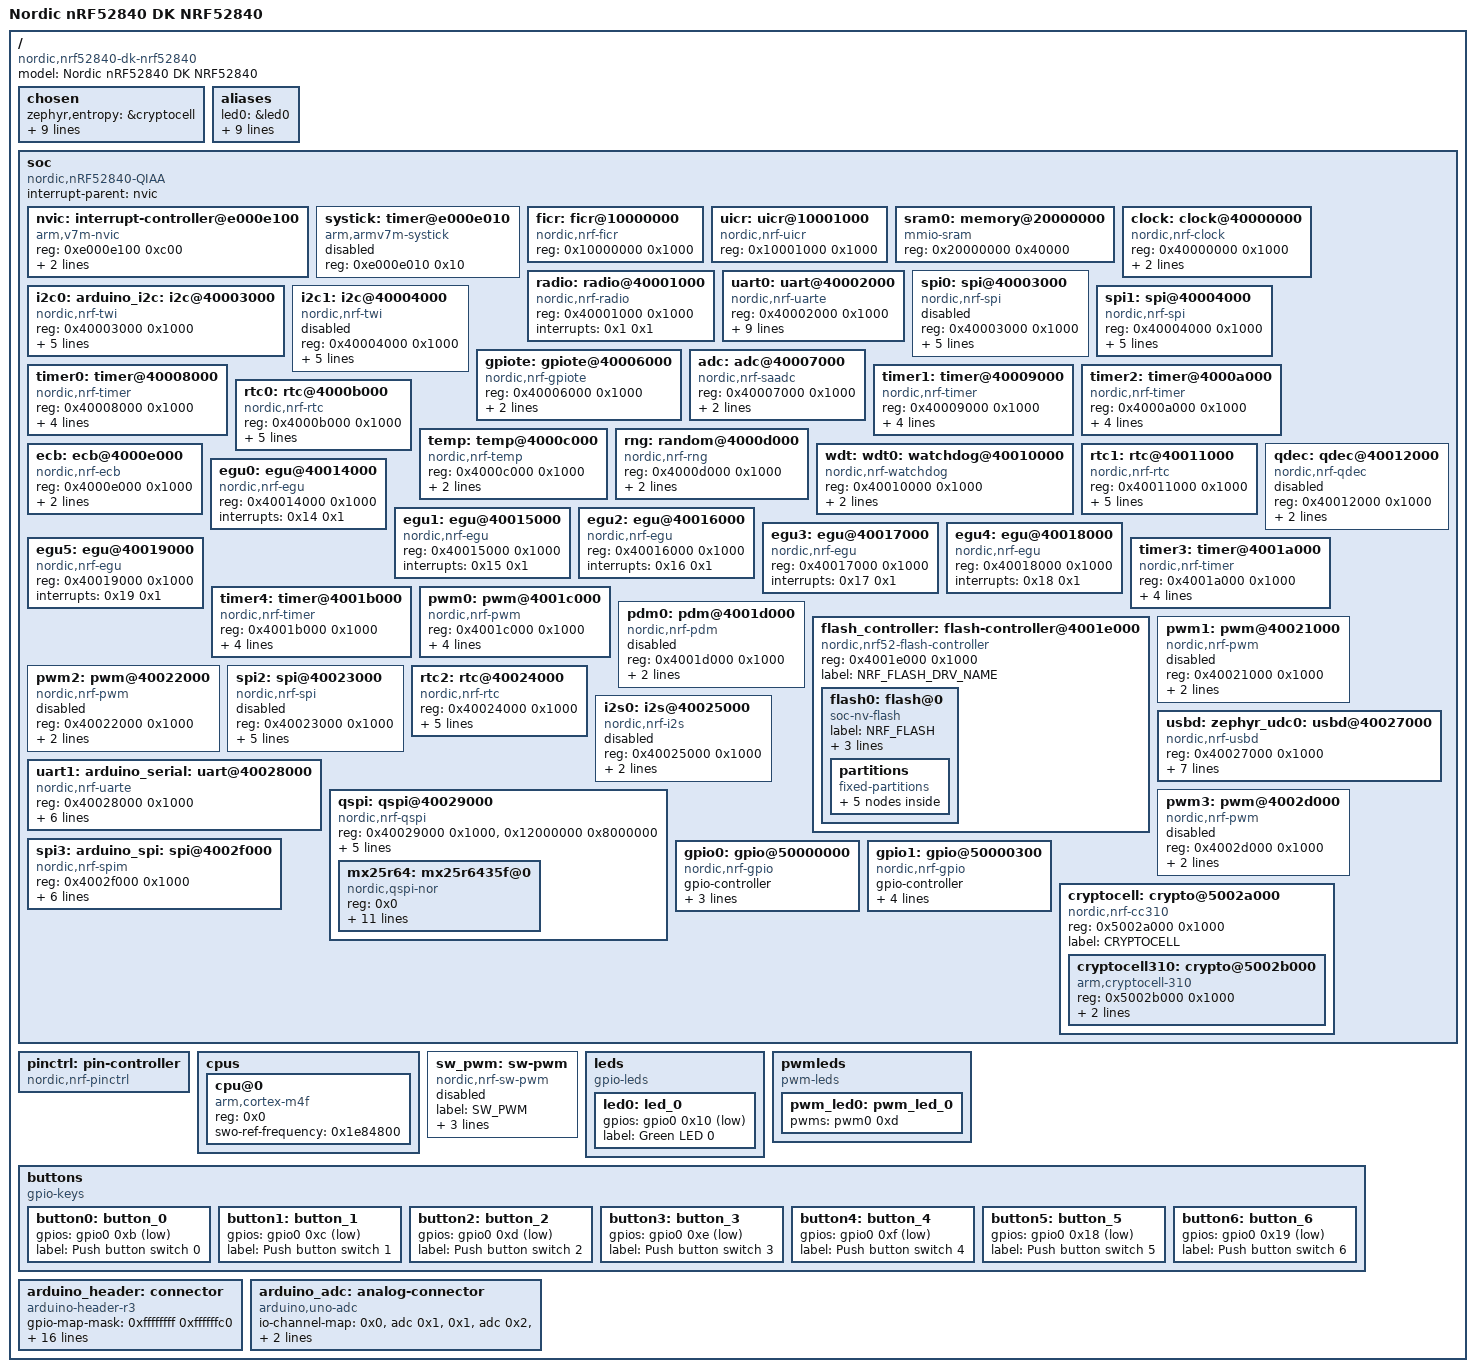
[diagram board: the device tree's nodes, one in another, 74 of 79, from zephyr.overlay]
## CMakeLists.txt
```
#
# Copyright (c) 2018 Nordic Semiconductor
#
# SPDX-License-Identifier: LicenseRef-Nordic-5-Clause
#
cmake_minimum_required(VERSION 3.20.0)

set(PM_STATIC_YML_FILE
  ${CMAKE_CURRENT_SOURCE_DIR}/boards/pm_static_${BOARD}.yml
  )

find_package(Zephyr REQUIRED HINTS $ENV{ZEPHYR_BASE})
project(NONE)

# NORDIC SDK APP START
target_sources(app PRIVATE
  src/main.c
  src/nus_midi.c
  src/button.c
)

# Include UART ASYNC API adapter
target_sources_ifdef(CONFIG_BT_NUS_UART_ASYNC_ADAPTER app PRIVATE
  src/uart_async_adapter.c
)

# Preinitialization related to Thingy:53 DFU
target_sources_ifdef(CONFIG_BOARD_THINGY53_NRF5340_CPUAPP app PRIVATE
  boards/thingy53.c
)
target_sources_ifdef(CONFIG_BOARD_THINGY53_NRF5340_CPUAPP_NS app PRIVATE
  boards/thingy53.c
)

# NORDIC SDK APP END

zephyr_library_include_directories(.)
```

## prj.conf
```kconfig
#
# Copyright (c) 2018 Nordic Semiconductor
#
# SPDX-License-Identifier: LicenseRef-Nordic-5-Clause
#

# Enable the UART driver
CONFIG_UART_ASYNC_API=y
CONFIG_NRFX_UARTE0=y
CONFIG_SERIAL=y

CONFIG_GPIO=y

# Make sure printk is printing to the UART console
CONFIG_CONSOLE=y
CONFIG_UART_CONSOLE=y

CONFIG_HEAP_MEM_POOL_SIZE=2048

CONFIG_BT=y
CONFIG_BT_PERIPHERAL=y
CONFIG_BT_DEVICE_NAME="midi"
CONFIG_BT_DEVICE_APPEARANCE=833
CONFIG_BT_MAX_CONN=1
CONFIG_BT_MAX_PAIRED=1

# Enable the NUS service
CONFIG_BT_NUS=n

# Enable bonding
CONFIG_BT_SETTINGS=y
CONFIG_FLASH=y
CONFIG_FLASH_PAGE_LAYOUT=y
CONFIG_FLASH_MAP=y
CONFIG_NVS=y
CONFIG_SETTINGS=y

# Enable DK LED and Buttons library
CONFIG_DK_LIBRARY=y

# This example requires more workqueue stack
CONFIG_SYSTEM_WORKQUEUE_STACK_SIZE=2048

# Config logger
CONFIG_LOG=y
CONFIG_USE_SEGGER_RTT=y
CONFIG_LOG_BACKEND_RTT=y
CONFIG_LOG_BACKEND_UART=n

CONFIG_ASSERT=y
```

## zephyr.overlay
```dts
/ {
	#address-cells = < 0x1 >;
	#size-cells = < 0x1 >;
	model = "Nordic nRF52840 DK NRF52840";
	compatible = "nordic,nrf52840-dk-nrf52840";
	chosen {
		zephyr,entropy = &cryptocell;
		zephyr,flash-controller = &flash_controller;
		zephyr,console = &uart0;
		zephyr,shell-uart = &uart0;
		zephyr,uart-mcumgr = &uart0;
		zephyr,bt-mon-uart = &uart0;
		zephyr,bt-c2h-uart = &uart0;
		zephyr,sram = &sram0;
		zephyr,flash = &flash0;
		zephyr,code-partition = &slot0_partition;
	};
	aliases {
		led0 = &led0;
		pwm-led0 = &pwm_led0;
		sw0 = &button0;
		sw1 = &button1;
		sw2 = &button2;
		sw3 = &button3;
		sw4 = &button4;
		sw5 = &button5;
		sw6 = &button6;
		bootloader-led0 = &led0;
	};
	soc {
		#address-cells = < 0x1 >;
		#size-cells = < 0x1 >;
		compatible = "nordic,nRF52840-QIAA", "nordic,nRF52840", "nordic,nRF52", "simple-bus";
		interrupt-parent = < &nvic >;
		ranges;
		nvic: interrupt-controller@e000e100 {
			#address-cells = < 0x1 >;
			compatible = "arm,v7m-nvic";
			reg = < 0xe000e100 0xc00 >;
			interrupt-controller;
			#interrupt-cells = < 0x2 >;
			arm,num-irq-priority-bits = < 0x3 >;
			phandle = < 0x1 >;
		};
		systick: timer@e000e010 {
			compatible = "arm,armv7m-systick";
			reg = < 0xe000e010 0x10 >;
			status = "disabled";
		};
		ficr: ficr@10000000 {
			compatible = "nordic,nrf-ficr";
			reg = < 0x10000000 0x1000 >;
			status = "okay";
		};
		uicr: uicr@10001000 {
			compatible = "nordic,nrf-uicr";
			reg = < 0x10001000 0x1000 >;
			status = "okay";
		};
		sram0: memory@20000000 {
			compatible = "mmio-sram";
			reg = < 0x20000000 0x40000 >;
		};
		clock: clock@40000000 {
			compatible = "nordic,nrf-clock";
			reg = < 0x40000000 0x1000 >;
			interrupts = < 0x0 0x1 >;
			status = "okay";
			label = "CLOCK";
		};
		radio: radio@40001000 {
			compatible = "nordic,nrf-radio";
			reg = < 0x40001000 0x1000 >;
			interrupts = < 0x1 0x1 >;
			status = "okay";
		};
		uart0: uart@40002000 {
			compatible = "nordic,nrf-uarte";
			reg = < 0x40002000 0x1000 >;
			interrupts = < 0x2 0x1 >;
			status = "okay";
			label = "UART_0";
			current-speed = < 0x1c200 >;
			tx-pin = < 0x6 >;
			rx-pin = < 0x8 >;
			rx-pull-up;
			rts-pin = < 0x5 >;
			cts-pin = < 0x7 >;
			cts-pull-up;
		};
		i2c0: arduino_i2c: i2c@40003000 {
			compatible = "nordic,nrf-twi";
			#address-cells = < 0x1 >;
			#size-cells = < 0x0 >;
			reg = < 0x40003000 0x1000 >;
			clock-frequency = < 0x186a0 >;
			interrupts = < 0x3 0x1 >;
			status = "okay";
			label = "I2C_0";
			sda-pin = < 0x1a >;
			scl-pin = < 0x1b >;
		};
		spi0: spi@40003000 {
			compatible = "nordic,nrf-spi";
			#address-cells = < 0x1 >;
			#size-cells = < 0x0 >;
			reg = < 0x40003000 0x1000 >;
			interrupts = < 0x3 0x1 >;
			status = "disabled";
			label = "SPI_0";
			sck-pin = < 0x1b >;
			mosi-pin = < 0x1a >;
			miso-pin = < 0x1d >;
		};
		i2c1: i2c@40004000 {
			compatible = "nordic,nrf-twi";
			#address-cells = < 0x1 >;
			#size-cells = < 0x0 >;
			reg = < 0x40004000 0x1000 >;
			clock-frequency = < 0x186a0 >;
			interrupts = < 0x4 0x1 >;
			status = "disabled";
			label = "I2C_1";
			sda-pin = < 0x1e >;
			scl-pin = < 0x1f >;
		};
		spi1: spi@40004000 {
			compatible = "nordic,nrf-spi";
			#address-cells = < 0x1 >;
			#size-cells = < 0x0 >;
			reg = < 0x40004000 0x1000 >;
			interrupts = < 0x4 0x1 >;
			status = "okay";
			label = "SPI_1";
			sck-pin = < 0x1f >;
			mosi-pin = < 0x1e >;
			miso-pin = < 0x28 >;
		};
		gpiote: gpiote@40006000 {
			compatible = "nordic,nrf-gpiote";
			reg = < 0x40006000 0x1000 >;
			interrupts = < 0x6 0x5 >;
			status = "okay";
			label = "GPIOTE_0";
		};
		adc: adc@40007000 {
			compatible = "nordic,nrf-saadc";
			reg = < 0x40007000 0x1000 >;
			interrupts = < 0x7 0x1 >;
			status = "okay";
			label = "ADC_0";
			#io-channel-cells = < 0x1 >;
			phandle = < 0x7 >;
		};
		timer0: timer@40008000 {
			compatible = "nordic,nrf-timer";
			status = "okay";
			reg = < 0x40008000 0x1000 >;
			cc-num = < 0x4 >;
			interrupts = < 0x8 0x1 >;
			prescaler = < 0x0 >;
			label = "TIMER_0";
		};
		timer1: timer@40009000 {
			compatible = "nordic,nrf-timer";
			status = "okay";
			reg = < 0x40009000 0x1000 >;
			cc-num = < 0x4 >;
			interrupts = < 0x9 0x1 >;
			prescaler = < 0x0 >;
			label = "TIMER_1";
		};
		timer2: timer@4000a000 {
			compatible = "nordic,nrf-timer";
			status = "okay";
			reg = < 0x4000a000 0x1000 >;
			cc-num = < 0x4 >;
			interrupts = < 0xa 0x1 >;
			prescaler = < 0x0 >;
			label = "TIMER_2";
			phandle = < 0x3 >;
		};
		rtc0: rtc@4000b000 {
			compatible = "nordic,nrf-rtc";
			reg = < 0x4000b000 0x1000 >;
			cc-num = < 0x3 >;
			interrupts = < 0xb 0x1 >;
			status = "okay";
			clock-frequency = < 0x8000 >;
			prescaler = < 0x1 >;
			label = "RTC_0";
		};
		temp: temp@4000c000 {
			compatible = "nordic,nrf-temp";
			reg = < 0x4000c000 0x1000 >;
			interrupts = < 0xc 0x1 >;
			status = "okay";
			label = "TEMP_0";
		};
		rng: random@4000d000 {
			compatible = "nordic,nrf-rng";
			reg = < 0x4000d000 0x1000 >;
			interrupts = < 0xd 0x1 >;
			status = "okay";
			label = "RNG";
		};
		ecb: ecb@4000e000 {
			compatible = "nordic,nrf-ecb";
			reg = < 0x4000e000 0x1000 >;
			interrupts = < 0xe 0x1 >;
			status = "okay";
			label = "ECB";
		};
		wdt: wdt0: watchdog@40010000 {
			compatible = "nordic,nrf-watchdog";
			reg = < 0x40010000 0x1000 >;
			interrupts = < 0x10 0x1 >;
			status = "okay";
			label = "WDT";
		};
		rtc1: rtc@40011000 {
			compatible = "nordic,nrf-rtc";
			reg = < 0x40011000 0x1000 >;
			cc-num = < 0x4 >;
			interrupts = < 0x11 0x1 >;
			status = "okay";
			clock-frequency = < 0x8000 >;
			prescaler = < 0x1 >;
			label = "RTC_1";
		};
		qdec: qdec@40012000 {
			compatible = "nordic,nrf-qdec";
			reg = < 0x40012000 0x1000 >;
			interrupts = < 0x12 0x1 >;
			status = "disabled";
			label = "QDEC";
		};
		egu0: egu@40014000 {
			compatible = "nordic,nrf-egu";
			reg = < 0x40014000 0x1000 >;
			interrupts = < 0x14 0x1 >;
			status = "okay";
		};
		egu1: egu@40015000 {
			compatible = "nordic,nrf-egu";
			reg = < 0x40015000 0x1000 >;
			interrupts = < 0x15 0x1 >;
			status = "okay";
		};
		egu2: egu@40016000 {
			compatible = "nordic,nrf-egu";
			reg = < 0x40016000 0x1000 >;
			interrupts = < 0x16 0x1 >;
			status = "okay";
		};
		egu3: egu@40017000 {
			compatible = "nordic,nrf-egu";
			reg = < 0x40017000 0x1000 >;
			interrupts = < 0x17 0x1 >;
			status = "okay";
		};
		egu4: egu@40018000 {
			compatible = "nordic,nrf-egu";
			reg = < 0x40018000 0x1000 >;
			interrupts = < 0x18 0x1 >;
			status = "okay";
		};
		egu5: egu@40019000 {
			compatible = "nordic,nrf-egu";
			reg = < 0x40019000 0x1000 >;
			interrupts = < 0x19 0x1 >;
			status = "okay";
		};
		timer3: timer@4001a000 {
			compatible = "nordic,nrf-timer";
			status = "okay";
			reg = < 0x4001a000 0x1000 >;
			cc-num = < 0x6 >;
			interrupts = < 0x1a 0x1 >;
			prescaler = < 0x0 >;
			label = "TIMER_3";
		};
		timer4: timer@4001b000 {
			compatible = "nordic,nrf-timer";
			status = "okay";
			reg = < 0x4001b000 0x1000 >;
			cc-num = < 0x6 >;
			interrupts = < 0x1b 0x1 >;
			prescaler = < 0x0 >;
			label = "TIMER_4";
		};
		pwm0: pwm@4001c000 {
			compatible = "nordic,nrf-pwm";
			reg = < 0x4001c000 0x1000 >;
			interrupts = < 0x1c 0x1 >;
			status = "okay";
			label = "PWM_0";
			#pwm-cells = < 0x1 >;
			ch0-pin = < 0xd >;
			ch0-inverted;
			phandle = < 0x5 >;
		};
		pdm0: pdm@4001d000 {
			compatible = "nordic,nrf-pdm";
			reg = < 0x4001d000 0x1000 >;
			interrupts = < 0x1d 0x1 >;
			status = "disabled";
			label = "PDM_0";
		};
		flash_controller: flash-controller@4001e000 {
			compatible = "nordic,nrf52-flash-controller";
			reg = < 0x4001e000 0x1000 >;
			#address-cells = < 0x1 >;
			#size-cells = < 0x1 >;
			label = "NRF_FLASH_DRV_NAME";
			flash0: flash@0 {
				compatible = "soc-nv-flash";
				label = "NRF_FLASH";
				erase-block-size = < 0x1000 >;
				write-block-size = < 0x4 >;
				reg = < 0x0 0x100000 >;
				partitions {
					compatible = "fixed-partitions";
					#address-cells = < 0x1 >;
					#size-cells = < 0x1 >;
					boot_partition: partition@0 {
						label = "mcuboot";
						reg = < 0x0 0xc000 >;
					};
					slot0_partition: partition@c000 {
						label = "image-0";
						reg = < 0xc000 0x67000 >;
					};
					slot1_partition: partition@73000 {
						label = "image-1";
						reg = < 0x73000 0x67000 >;
					};
					scratch_partition: partition@da000 {
						label = "image-scratch";
						reg = < 0xda000 0x1e000 >;
					};
					storage_partition: partition@f8000 {
						label = "storage";
						reg = < 0xf8000 0x8000 >;
					};
				};
			};
		};
		pwm1: pwm@40021000 {
			compatible = "nordic,nrf-pwm";
			reg = < 0x40021000 0x1000 >;
			interrupts = < 0x21 0x1 >;
			status = "disabled";
			label = "PWM_1";
			#pwm-cells = < 0x1 >;
		};
		pwm2: pwm@40022000 {
			compatible = "nordic,nrf-pwm";
			reg = < 0x40022000 0x1000 >;
			interrupts = < 0x22 0x1 >;
			status = "disabled";
			label = "PWM_2";
			#pwm-cells = < 0x1 >;
		};
		spi2: spi@40023000 {
			compatible = "nordic,nrf-spi";
			#address-cells = < 0x1 >;
			#size-cells = < 0x0 >;
			reg = < 0x40023000 0x1000 >;
			interrupts = < 0x23 0x1 >;
			status = "disabled";
			label = "SPI_2";
			sck-pin = < 0x13 >;
			mosi-pin = < 0x14 >;
			miso-pin = < 0x15 >;
		};
		rtc2: rtc@40024000 {
			compatible = "nordic,nrf-rtc";
			reg = < 0x40024000 0x1000 >;
			cc-num = < 0x4 >;
			interrupts = < 0x24 0x1 >;
			status = "okay";
			clock-frequency = < 0x8000 >;
			prescaler = < 0x1 >;
			label = "RTC_2";
		};
		i2s0: i2s@40025000 {
			compatible = "nordic,nrf-i2s";
			#address-cells = < 0x1 >;
			#size-cells = < 0x0 >;
			reg = < 0x40025000 0x1000 >;
			interrupts = < 0x25 0x1 >;
			status = "disabled";
			label = "I2S_0";
		};
		usbd: zephyr_udc0: usbd@40027000 {
			compatible = "nordic,nrf-usbd";
			reg = < 0x40027000 0x1000 >;
			interrupts = < 0x27 0x1 >;
			num-bidir-endpoints = < 0x1 >;
			num-in-endpoints = < 0x7 >;
			num-out-endpoints = < 0x7 >;
			num-isoin-endpoints = < 0x1 >;
			num-isoout-endpoints = < 0x1 >;
			status = "okay";
			label = "USBD";
		};
		uart1: arduino_serial: uart@40028000 {
			compatible = "nordic,nrf-uarte";
			reg = < 0x40028000 0x1000 >;
			interrupts = < 0x28 0x1 >;
			status = "okay";
			label = "UART_1";
			current-speed = < 0x1c200 >;
			rx-pin = < 0x21 >;
			rx-pull-up;
			tx-pin = < 0x22 >;
		};
		qspi: qspi@40029000 {
			compatible = "nordic,nrf-qspi";
			#address-cells = < 0x1 >;
			#size-cells = < 0x0 >;
			reg = < 0x40029000 0x1000 >, < 0x12000000 0x8000000 >;
			reg-names = "qspi", "qspi_mm";
			interrupts = < 0x29 0x1 >;
			status = "okay";
			label = "QSPI";
			sck-pin = < 0x13 >;
			io-pins = < 0x14 >, < 0x15 >, < 0x16 >, < 0x17 >;
			csn-pins = < 0x11 >;
			mx25r64: mx25r6435f@0 {
				compatible = "nordic,qspi-nor";
				reg = < 0x0 >;
				writeoc = "pp4io";
				readoc = "read4io";
				sck-frequency = < 0x7a1200 >;
				label = "MX25R64";
				jedec-id = [ C2 28 17 ];
				sfdp-bfp = [ E5 20 F1 FF FF FF FF 03 44 EB 08 6B 08 3B 04 BB EE FF FF FF FF FF 00 FF FF FF 00 FF 0C 20 0F 52 10 D8 00 FF 23 72 F5 00 82 ED 04 CC 44 83 68 44 30 B0 30 B0 F7 C4 D5 5C 00 BE 29 FF F0 D0 FF FF ];
				size = < 0x4000000 >;
				has-dpd;
				t-enter-dpd = < 0x2710 >;
				t-exit-dpd = < 0x88b8 >;
			};
		};
		pwm3: pwm@4002d000 {
			compatible = "nordic,nrf-pwm";
			reg = < 0x4002d000 0x1000 >;
			interrupts = < 0x2d 0x1 >;
			status = "disabled";
			label = "PWM_3";
			#pwm-cells = < 0x1 >;
		};
		spi3: arduino_spi: spi@4002f000 {
			compatible = "nordic,nrf-spim";
			#address-cells = < 0x1 >;
			#size-cells = < 0x0 >;
			reg = < 0x4002f000 0x1000 >;
			interrupts = < 0x2f 0x1 >;
			status = "okay";
			label = "SPI_3";
			sck-pin = < 0x2f >;
			miso-pin = < 0x2e >;
			mosi-pin = < 0x2d >;
			cs-gpios = < &arduino_header 0x10 0x1 >;
		};
		gpio0: gpio@50000000 {
			compatible = "nordic,nrf-gpio";
			gpio-controller;
			reg = < 0x50000000 0x200 0x50000500 0x300 >;
			#gpio-cells = < 0x2 >;
			label = "GPIO_0";
			status = "okay";
			port = < 0x0 >;
			phandle = < 0x4 >;
		};
		gpio1: gpio@50000300 {
			compatible = "nordic,nrf-gpio";
			gpio-controller;
			reg = < 0x50000300 0x200 0x50000800 0x300 >;
			#gpio-cells = < 0x2 >;
			ngpios = < 0x10 >;
			label = "GPIO_1";
			status = "okay";
			port = < 0x1 >;
			phandle = < 0x6 >;
		};
		cryptocell: crypto@5002a000 {
			compatible = "nordic,nrf-cc310";
			reg = < 0x5002a000 0x1000 >;
			label = "CRYPTOCELL";
			status = "okay";
			#address-cells = < 0x1 >;
			#size-cells = < 0x1 >;
			cryptocell310: crypto@5002b000 {
				compatible = "arm,cryptocell-310";
				reg = < 0x5002b000 0x1000 >;
				interrupts = < 0x2a 0x1 >;
				label = "CRYPTOCELL310";
			};
		};
	};
	pinctrl: pin-controller {
		compatible = "nordic,nrf-pinctrl";
	};
	cpus {
		#address-cells = < 0x1 >;
		#size-cells = < 0x0 >;
		cpu@0 {
			device_type = "cpu";
			compatible = "arm,cortex-m4f";
			reg = < 0x0 >;
			swo-ref-frequency = < 0x1e84800 >;
		};
	};
	sw_pwm: sw-pwm {
		compatible = "nordic,nrf-sw-pwm";
		status = "disabled";
		label = "SW_PWM";
		generator = < &timer2 >;
		channel-count = < 0x3 >;
		clock-prescaler = < 0x0 >;
		#pwm-cells = < 0x1 >;
	};
	leds {
		compatible = "gpio-leds";
		led0: led_0 {
			gpios = < &gpio0 0x10 0x1 >;
			label = "Green LED 0";
		};
		// led1: led_1 {
		// 	gpios = < &gpio0 0xe 0x1 >;
		// 	label = "Green LED 1";
		// };
		// led2: led_2 {
		// 	gpios = < &gpio0 0xf 0x1 >;
		// 	label = "Green LED 2";
		// };
		// led3: led_3 {
		// 	gpios = < &gpio0 0x10 0x1 >;
		// 	label = "Green LED 3";
		// };
	};
	pwmleds {
		compatible = "pwm-leds";
		pwm_led0: pwm_led_0 {
			pwms = < &pwm0 0xd >;
		};
	};
	buttons {
		compatible = "gpio-keys";
		button0: button_0 {
			gpios = < &gpio0 0xb 0x11 >;
			label = "Push button switch 0";
		};
		button1: button_1 {
			gpios = < &gpio0 0xc 0x11 >;
			label = "Push button switch 1";
		};
		button2: button_2 {
			gpios = < &gpio0 0xd 0x11 >;
			label = "Push button switch 2";
		};
		button3: button_3 {
			gpios = < &gpio0 0xe 0x11 >;
			label = "Push button switch 3";
		};
		button4: button_4 {
			gpios = < &gpio0 0xf 0x11 >;
			label = "Push button switch 4";
		};
		button5: button_5 {
			gpios = < &gpio0 0x18 0x11 >;
			label = "Push button switch 5";
		};
		button6: button_6 {
			gpios = < &gpio0 0x19 0x11 >;
			label = "Push button switch 6";
		};
		
	};
	arduino_header: connector {
		compatible = "arduino-header-r3";
		#gpio-cells = < 0x2 >;
		gpio-map-mask = < 0xffffffff 0xffffffc0 >;
		gpio-map-pass-thru = < 0x0 0x3f >;
		gpio-map = < 0x0 0x0 &gpio0 0x3 0x0 >, < 0x1 0x0 &gpio0 0x4 0x0 >, < 0x2 0x0 &gpio0 0x1c 0x0 >, < 0x3 0x0 &gpio0 0x1d 0x0 >, < 0x4 0x0 &gpio0 0x1e 0x0 >, < 0x5 0x0 &gpio0 0x1f 0x0 >, < 0x6 0x0 &gpio1 0x1 0x0 >, < 0x7 0x0 &gpio1 0x2 0x0 >, < 0x8 0x0 &gpio1 0x3 0x0 >, < 0x9 0x0 &gpio1 0x4 0x0 >, < 0xa 0x0 &gpio1 0x5 0x0 >, < 0xb 0x0 &gpio1 0x6 0x0 >, < 0xc 0x0 &gpio1 0x7 0x0 >, < 0xd 0x0 &gpio1 0x8 0x0 >, < 0xe 0x0 &gpio1 0xa 0x0 >, < 0xf 0x0 &gpio1 0xb 0x0 >, < 0x10 0x0 &gpio1 0xc 0x0 >, < 0x11 0x0 &gpio1 0xd 0x0 >, < 0x12 0x0 &gpio1 0xe 0x0 >, < 0x13 0x0 &gpio1 0xf 0x0 >, < 0x14 0x0 &gpio0 0x1a 0x0 >, < 0x15 0x0 &gpio0 0x1b 0x0 >;
		phandle = < 0x2 >;
	};
	arduino_adc: analog-connector {
		compatible = "arduino,uno-adc";
		#io-channel-cells = < 0x1 >;
		io-channel-map = < 0x0 &adc 0x1 >, < 0x1 &adc 0x2 >, < 0x2 &adc 0x4 >, < 0x3 &adc 0x5 >, < 0x4 &adc 0x6 >, < 0x5 &adc 0x7 >;
	};
};
```

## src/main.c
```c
/*
 * Copyright (c) 2018 Nordic Semiconductor ASA
 *
 * SPDX-License-Identifier: LicenseRef-Nordic-5-Clause
 */

/** @file
 *  @brief Nordic UART Bridge Service (NUS) sample
 */
#include "uart_async_adapter.h"

#include <zephyr/types.h>
#include <zephyr.h>
#include <drivers/uart.h>
#include <usb/usb_device.h>

#include <device.h>
#include <soc.h>

#include <bluetooth/bluetooth.h>
#include <bluetooth/uuid.h>
#include <bluetooth/gatt.h>
#include <bluetooth/hci.h>

#include "nus_midi.h"
#include "button.h"

// #include <dk_buttons_and_leds.h>

#include <settings/settings.h>

#include <stdio.h>
#include <stdlib.h>
#include <drivers/gpio.h>
#include <logging/log.h>

#define LOG_MODULE_NAME peripheral_uart
LOG_MODULE_REGISTER(LOG_MODULE_NAME);

#define STACKSIZE CONFIG_BT_NUS_THREAD_STACK_SIZE
#define PRIORITY 7

#define DEVICE_NAME CONFIG_BT_DEVICE_NAME
#define DEVICE_NAME_LEN	(sizeof(DEVICE_NAME) - 1)

// #define RUN_STATUS_LED DK_LED1
#define RUN_LED_BLINK_INTERVAL 700

// #define CON_STATUS_LED DK_LED2

// #define KEY_PASSKEY_ACCEPT DK_BTN1_MSK
// #define KEY_PASSKEY_REJECT DK_BTN2_MSK

#define UART_BUF_SIZE CONFIG_BT_NUS_UART_BUFFER_SIZE
#define UART_WAIT_FOR_BUF_DELAY K_MSEC(50)
#define UART_WAIT_FOR_RX CONFIG_BT_NUS_UART_RX_WAIT_TIME

static K_SEM_DEFINE(ble_init_ok, 0, 1);

static struct bt_conn *current_conn;
static struct bt_conn *auth_conn;

static const struct device *uart;
static struct k_work_delayable uart_work;

struct uart_data_t {
	void *fifo_reserved;
	uint8_t data[UART_BUF_SIZE];
	uint16_t len;
};

static K_FIFO_DEFINE(fifo_uart_tx_data);
static K_FIFO_DEFINE(fifo_uart_rx_data);

static const struct bt_data ad[] = {
	BT_DATA_BYTES(BT_DATA_FLAGS, (BT_LE_AD_GENERAL | BT_LE_AD_NO_BREDR)),
	BT_DATA(BT_DATA_NAME_COMPLETE, DEVICE_NAME, DEVICE_NAME_LEN),
};

static const struct bt_data sd[] = {
	BT_DATA_BYTES(BT_DATA_UUID128_ALL, MIDI_BT_UUID_NUS_VAL),
};

#if CONFIG_BT_NUS_UART_ASYNC_ADAPTER
UART_ASYNC_ADAPTER_INST_DEFINE(async_adapter);
#else
static const struct device *const async_adapter;
#endif

static void uart_cb(const struct device *dev, struct uart_event *evt, void *user_data)
{
	ARG_UNUSED(dev);

	static uint8_t *current_buf;
	static size_t aborted_len;
	static bool buf_release;
	struct uart_data_t *buf;
	static uint8_t *aborted_buf;

	switch (evt->type) {
	case UART_TX_DONE:
		LOG_DBG("tx_done");
		if ((evt->data.tx.len == 0) ||
		    (!evt->data.tx.buf)) {
			return;
		}

		if (aborted_buf) {
			buf = CONTAINER_OF(aborted_buf, struct uart_data_t,
					   data);
			aborted_buf = NULL;
			aborted_len = 0;
		} else {
			buf = CONTAINER_OF(evt->data.tx.buf, struct uart_data_t,
					   data);
		}

		k_free(buf);

		buf = k_fifo_get(&fifo_uart_tx_data, K_NO_WAIT);
		if (!buf) {
			return;
		}

		if (uart_tx(uart, buf->data, buf->len, SYS_FOREVER_MS)) {
			LOG_WRN("Failed to send data over UART");
		}

		break;

	case UART_RX_RDY:
		LOG_DBG("rx_rdy");
		buf = CONTAINER_OF(evt->data.rx.buf, struct uart_data_t, data);
		buf->len += evt->data.rx.len;
		buf_release = false;

		if (buf->len == UART_BUF_SIZE) {
			k_fifo_put(&fifo_uart_rx_data, buf);
		} else if ((evt->data.rx.buf[buf->len - 1] == '\n') ||
			  (evt->data.rx.buf[buf->len - 1] == '\r')) {
			k_fifo_put(&fifo_uart_rx_data, buf);
			current_buf = evt->data.rx.buf;
			buf_release = true;
			uart_rx_disable(uart);
		}

		break;

	case UART_RX_DISABLED:
		LOG_DBG("rx_disabled");
		buf = k_malloc(sizeof(*buf));
		if (buf) {
			buf->len = 0;
		} else {
			LOG_WRN("Not able to allocate UART receive buffer");
			k_work_reschedule(&uart_work, UART_WAIT_FOR_BUF_DELAY);
			return;
		}

		uart_rx_enable(uart, buf->data, sizeof(buf->data),
			       UART_WAIT_FOR_RX);

		break;

	case UART_RX_BUF_REQUEST:
		LOG_DBG("rx_buf_request");
		buf = k_malloc(sizeof(*buf));
		if (buf) {
			buf->len = 0;
			uart_rx_buf_rsp(uart, buf->data, sizeof(buf->data));
		} else {
			LOG_WRN("Not able to allocate UART receive buffer");
		}

		break;

	case UART_RX_BUF_RELEASED:
		LOG_DBG("rx_buf_released");
		buf = CONTAINER_OF(evt->data.rx_buf.buf, struct uart_data_t,
				   data);
		if (buf_release && (current_buf != evt->data.rx_buf.buf)) {
			k_free(buf);
			buf_release = false;
			current_buf = NULL;
		}

		break;

	case UART_TX_ABORTED:
			LOG_DBG("tx_aborted");
			if (!aborted_buf) {
				aborted_buf = (uint8_t *)evt->data.tx.buf;
			}

			aborted_len += evt->data.tx.len;
			buf = CONTAINER_OF(aborted_buf, struct uart_data_t,
					   data);

			uart_tx(uart, &buf->data[aborted_len],
				buf->len - aborted_len, SYS_FOREVER_MS);

		break;

	default:
		break;
	}
}

static void uart_work_handler(struct k_work *item)
{
	struct uart_data_t *buf;

	buf = k_malloc(sizeof(*buf));
	if (buf) {
		buf->len = 0;
	} else {
		LOG_WRN("Not able to allocate UART receive buffer");
		k_work_reschedule(&uart_work, UART_WAIT_FOR_BUF_DELAY);
		return;
	}

	uart_rx_enable(uart, buf->data, sizeof(buf->data), UART_WAIT_FOR_RX);
}

static bool uart_test_async_api(const struct device *dev)
{
	const struct uart_driver_api *api =
			(const struct uart_driver_api *)dev->api;

	return (api->callback_set != NULL);
}

static int uart_init(void)
{
	int err;
	int pos;
	struct uart_data_t *rx;
	struct uart_data_t *tx;

	uart = device_get_binding(CONFIG_BT_NUS_UART_DEV);
	if (!uart) {
		return -ENXIO;
	}

	if (IS_ENABLED(CONFIG_USB_DEVICE_STACK)) {
		err = usb_enable(NULL);
		if (err) {
			LOG_ERR("Failed to enable USB");
			return err;
		}
	}

	rx = k_malloc(sizeof(*rx));
	if (rx) {
		rx->len = 0;
	} else {
		return -ENOMEM;
	}

	k_work_init_delayable(&uart_work, uart_work_handler);


	if (IS_ENABLED(CONFIG_BT_NUS_UART_ASYNC_ADAPTER) && !uart_test_async_api(uart)) {
		/* Implement API adapter */
		uart_async_adapter_init(async_adapter, uart);
		uart = async_adapter;
	}

	err = uart_callback_set(uart, uart_cb, NULL);
	if (err) {
		LOG_ERR("Cannot initialize UART callback");
		return err;
	}

	if (IS_ENABLED(CONFIG_UART_LINE_CTRL)) {
		LOG_INF("Wait for DTR");
		while (true) {
			uint32_t dtr = 0;

			uart_line_ctrl_get(uart, UART_LINE_CTRL_DTR, &dtr);
			if (dtr) {
				break;
			}
			/* Give CPU resources to low priority threads. */
			k_sleep(K_MSEC(100));
		}
		LOG_INF("DTR set");
		err = uart_line_ctrl_set(uart, UART_LINE_CTRL_DCD, 1);
		if (err) {
			LOG_WRN("Failed to set DCD, ret code %d", err);
		}
		err = uart_line_ctrl_set(uart, UART_LINE_CTRL_DSR, 1);
		if (err) {
			LOG_WRN("Failed to set DSR, ret code %d", err);
		}
	}

	tx = k_malloc(sizeof(*tx));

	if (tx) {
		pos = snprintf(tx->data, sizeof(tx->data),
			       "Starting BLE MIDI service example\r\n");

		if ((pos < 0) || (pos >= sizeof(tx->data))) {
			k_free(tx);
			LOG_ERR("snprintf returned %d", pos);
			return -ENOMEM;
		}

		tx->len = pos;
	} else {
		return -ENOMEM;
	}

	err = uart_tx(uart, tx->data, tx->len, SYS_FOREVER_MS);
	if (err) {
		LOG_ERR("Cannot display welcome message (err: %d)", err);
		return err;
	}

	return uart_rx_enable(uart, rx->data, sizeof(rx->data), 50);
}

static void connected(struct bt_conn *conn, uint8_t err)
{
	char addr[BT_ADDR_LE_STR_LEN];

	if (err) {
		LOG_ERR("Connection failed (err %u)", err);
		return;
	}

	bt_addr_le_to_str(bt_conn_get_dst(conn), addr, sizeof(addr));
	LOG_INF("Connected %s", log_strdup(addr));

	current_conn = bt_conn_ref(conn);

	// dk_set_led_on(CON_STATUS_LED);
}

static void disconnected(struct bt_conn *conn, uint8_t reason)
{
	char addr[BT_ADDR_LE_STR_LEN];

	bt_addr_le_to_str(bt_conn_get_dst(conn), addr, sizeof(addr));

	LOG_INF("Disconnected: %s (reason %u)", log_strdup(addr), reason);

	if (auth_conn) {
		bt_conn_unref(auth_conn);
		auth_conn = NULL;
	}

	if (current_conn) {
		bt_conn_unref(current_conn);
		current_conn = NULL;
		// dk_set_led_off(CON_STATUS_LED);
	}
}

#ifdef CONFIG_BT_NUS_SECURITY_ENABLED
static void security_changed(struct bt_conn *conn, bt_security_t level,
			     enum bt_security_err err)
{
	char addr[BT_ADDR_LE_STR_LEN];

	bt_addr_le_to_str(bt_conn_get_dst(conn), addr, sizeof(addr));

	if (!err) {
		LOG_INF("Security changed: %s level %u", log_strdup(addr),
			level);
	} else {
		LOG_WRN("Security failed: %s level %u err %d", log_strdup(addr),
			level, err);
	}
}
#endif

BT_CONN_CB_DEFINE(conn_callbacks) = {
	.connected    = connected,
	.disconnected = disconnected,
#ifdef CONFIG_BT_NUS_SECURITY_ENABLED
	.security_changed = security_changed,
#endif
};

#if defined(CONFIG_BT_NUS_SECURITY_ENABLED)
static void auth_passkey_display(struct bt_conn *conn, unsigned int passkey)
{
	char addr[BT_ADDR_LE_STR_LEN];

	bt_addr_le_to_str(bt_conn_get_dst(conn), addr, sizeof(addr));

	LOG_INF("Passkey for %s: %06u", log_strdup(addr), passkey);
}

static void auth_passkey_confirm(struct bt_conn *conn, unsigned int passkey)
{
	char addr[BT_ADDR_LE_STR_LEN];

	auth_conn = bt_conn_ref(conn);

	bt_addr_le_to_str(bt_conn_get_dst(conn), addr, sizeof(addr));

	LOG_INF("Passkey for %s: %06u", log_strdup(addr), passkey);
	LOG_INF("Press Button 1 to confirm, Button 2 to reject.");
}


static void auth_cancel(struct bt_conn *conn)
{
	char addr[BT_ADDR_LE_STR_LEN];

	bt_addr_le_to_str(bt_conn_get_dst(conn), addr, sizeof(addr));

	LOG_INF("Pairing cancelled: %s", log_strdup(addr));
}


static void pairing_complete(struct bt_conn *conn, bool bonded)
{
	char addr[BT_ADDR_LE_STR_LEN];

	bt_addr_le_to_str(bt_conn_get_dst(conn), addr, sizeof(addr));

	LOG_INF("Pairing completed: %s, bonded: %d", log_strdup(addr),
		bonded);
}


static void pairing_failed(struct bt_conn *conn, enum bt_security_err reason)
{
	char addr[BT_ADDR_LE_STR_LEN];

	bt_addr_le_to_str(bt_conn_get_dst(conn), addr, sizeof(addr));

	LOG_INF("Pairing failed conn: %s, reason %d", log_strdup(addr),
		reason);
}


static struct bt_conn_auth_cb conn_auth_callbacks = {
	.passkey_display = auth_passkey_display,
	.passkey_confirm = auth_passkey_confirm,
	.cancel = auth_cancel,
	.pairing_complete = pairing_complete,
	.pairing_failed = pairing_failed
};
#else
static struct bt_conn_auth_cb conn_auth_callbacks;
#endif

static void bt_receive_cb(struct bt_conn *conn, const uint8_t *const data,
			  uint16_t len)
{
	int err;
	char addr[BT_ADDR_LE_STR_LEN] = {0};

	bt_addr_le_to_str(bt_conn_get_dst(conn), addr, ARRAY_SIZE(addr));

	LOG_INF("Received data from: %s", log_strdup(addr));

	for (uint16_t pos = 0; pos != len;) {
		struct uart_data_t *tx = k_malloc(sizeof(*tx));

		if (!tx) {
			LOG_WRN("Not able to allocate UART send data buffer");
			return;
		}

		/* Keep the last byte of TX buffer for potential LF char. */
		size_t tx_data_size = sizeof(tx->data) - 1;

		if ((len - pos) > tx_data_size) {
			tx->len = tx_data_size;
		} else {
			tx->len = (len - pos);
		}

		memcpy(tx->data, &data[pos], tx->len);

		pos += tx->len;

		/* Append the LF character when the CR character triggered
		 * transmission from the peer.
		 */
		if ((pos == len) && (data[len - 1] == '\r')) {
			tx->data[tx->len] = '\n';
			tx->len++;
		}

		err = uart_tx(uart, tx->data, tx->len, SYS_FOREVER_MS);
		if (err) {
			k_fifo_put(&fifo_uart_tx_data, tx);
		}
	}
}
/*
static struct bt_nus_cb nus_cb = {
	.received = bt_receive_cb,
};
*/

void bt_send_enabled(enum bt_nus_send_status status)
{
    LOG_INF("notification callback");
    LOG_INF("notifications %s", (status==BT_NUS_SEND_STATUS_ENABLED)?"enabled":"disabled");
}

static struct bt_nus_cb nus_cb = {
	.received = bt_receive_cb,
    .send_enabled = bt_send_enabled,
};

void error(void)
{
	// dk_set_leds_state(DK_ALL_LEDS_MSK, DK_NO_LEDS_MSK);

	while (true) {
		/* Spin for ever */
		k_sleep(K_MSEC(1000));
	}
}

// #ifdef CONFIG_BT_NUS_SECURITY_ENABLED
// static void num_comp_reply(bool accept)
// {
// 	if (accept) {
// 		bt_conn_auth_passkey_confirm(auth_conn);
// 		LOG_INF("Numeric Match, conn %p", (void *)auth_conn);
// 	} else {
// 		bt_conn_auth_cancel(auth_conn);
// 		LOG_INF("Numeric Reject, conn %p", (void *)auth_conn);
// 	}

// 	bt_conn_unref(auth_conn);
// 	auth_conn = NULL;
// }

// void button_changed(uint32_t button_state, uint32_t has_changed)
// {
// 	uint32_t buttons = button_state & has_changed;

// 	if (auth_conn) {
// 		if (buttons & KEY_PASSKEY_ACCEPT) {
// 			num_comp_reply(true);
// 		}

// 		if (buttons & KEY_PASSKEY_REJECT) {
// 			num_comp_reply(false);
// 		}
// 	}
// }
// #endif /* CONFIG_BT_NUS_SECURITY_ENABLED */

// static void configure_gpio(void)
// {
// 	int err;

// #ifdef CONFIG_BT_NUS_SECURITY_ENABLED
// 	err = dk_buttons_init(button_changed);
// 	if (err) {
// 		LOG_ERR("Cannot init buttons (err: %d)", err);
// 	}
// #endif /* CONFIG_BT_NUS_SECURITY_ENABLED */

// 	// err = dk_leds_init();
// 	// if (err) {
// 	// 	LOG_ERR("Cannot init LEDs (err: %d)", err);
// 	// }
// }

// static unsigned char message[];
void main(void)
{
	// int blink_status = 0;
	int err = 0;

	// configure_gpio();
	button_check();
	err = uart_init();
	if (err) {
		error();
	}

	if (IS_ENABLED(CONFIG_BT_NUS_SECURITY_ENABLED)) {
		bt_conn_auth_cb_register(&conn_auth_callbacks);
	}

	err = bt_enable(NULL);
	if (err) {
		error();
	}

	LOG_INF("Bluetooth initialized");

	k_sem_give(&ble_init_ok);

	if (IS_ENABLED(CONFIG_SETTINGS)) {
		settings_load();
	}

	err = bt_nus_init(&nus_cb);
	if (err) {
		LOG_ERR("Failed to initialize UART service (err: %d)", err);
		return;
	}

	err = bt_le_adv_start(BT_LE_ADV_CONN, ad, ARRAY_SIZE(ad), sd,
			      ARRAY_SIZE(sd));
	if (err) {
		LOG_ERR("Advertising failed to start (err %d)", err);
		return;
	}
}

void ble_write_thread(void)
{
	/* Don't go any further until BLE is initialized */
	k_sem_take(&ble_init_ok, K_FOREVER);
	
	for (;;) {
		k_sleep(K_MSEC(RUN_LED_BLINK_INTERVAL));
    
		if (bt_nus_send(NULL, messages, sizeof(messages))) {
			LOG_WRN("Failed to send data over BLE connection");
		}

		messages[3] = 0x00;
		messages[4] = 0x00;
        // for(int i = 0; i < 5; i++) {
        //     printk("message[%d] = 0x%02X\n", i, (unsigned int)(messages[i] & 0XFF));
        // }
		// printk("midi message send\n");
	}
}

K_THREAD_DEFINE(ble_write_thread_id, STACKSIZE, ble_write_thread, NULL, NULL,
		NULL, PRIORITY, 0, 0);
```

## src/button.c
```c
/*
 * Copyright (c) 2016 Open-RnD Sp. z o.o.
 * Copyright (c) 2020 Nordic Semiconductor ASA
 *
 * SPDX-License-Identifier: Apache-2.0
 */

#include <zephyr.h>
#include <device.h>
#include <drivers/gpio.h>
#include <sys/util.h>
#include <sys/printk.h>
#include <inttypes.h>
#include <string.h>
#include "button.h"

// define callback handler named button_pressed
unsigned char messages[5] = {0x80, 0x80, 0x90, 0x00, 0x00};
unsigned char chord;

void button_pressed(const struct device *dev, struct gpio_callback *cb, uint32_t pins) {
    printk("Button pressed at pin %" PRIu32 "\n", pins);

    switch(pins) {
        case 33554432:
            chord = 0x3C;
            break;
        case 16777216:
            chord = 0x3E;
            break;
        case 32768:
            chord = 0x40;
            break;
        case 16384:
            chord = 0x41;
            break;
        case 8192:
            chord = 0x43;
            break;
        case 4096:
            chord = 0x45;
            break;
        case 2048:
            chord = 0x47;
            break;
        default:
            chord = 0x3C;
            break;
    }

    messages[3] = chord;
    messages[4] = 0x7F;

    for(int i = 0; i < 7; i++) {
        gpio_pin_set_dt(&buttons[i], 0);
    }

    printk("\nchord = 0x%02X\n", (unsigned int)(chord & 0XFF));
    for(int i = 0; i < 5; i++) {
        printk("message[%d] = 0x%02X\n", i, (unsigned int)(messages[i] & 0XFF));
    }
}

void button_check(void){
	int ret[7];
        
    /* button available check */
    for(int i = 0; i < 7; i++) {
        if (!device_is_ready(buttons[i].port)) {
            printk("Error: button device %s is not ready\n",
                   buttons[i].port->name);
            return;
        }
    }
        
    /* adding extra flags : GPIO_INPUT */
    for(int i = 0; i < 7; i++) {
        ret[i] = gpio_pin_configure_dt(&buttons[i], GPIO_INPUT);

        if (ret[i] != 0) {
            printk("Error %d: failed to configure %s pin %d\n",
                   ret[i], buttons[i].port->name, buttons[i].pin);
            return;
        }
    }
        
    /* adding extra flags : GPIO_INT_EDGE_TO_ACTIVE */
    /* button port and pin available check */
    for(int i = 0; i < 7; i++) {
        ret[i] = gpio_pin_interrupt_configure_dt(&buttons[i], GPIO_INT_EDGE_TO_ACTIVE);

        if (ret[i] != 0) {
            printk("Error %d: failed to configure interrupt on %s pin %d\n",
                   ret[i], buttons[i].port->name, buttons[i].pin);
            return;
        }
    }
        
    /* assign callback handler to gpio_callback */
    for(int i = 0; i < 7; i++) {
        gpio_init_callback(&button_cb_data[i], button_pressed, BIT(buttons[i].pin));
    }

    /* add callback to port*/
    for(int i = 0; i < 7; i++) {
        gpio_add_callback(buttons[i].port, &button_cb_data[i]);
        printk("Set up button at %s pin %d\n", buttons[i].port->name, buttons[i].pin);
    }

	printk("Press the button\n");
}
```

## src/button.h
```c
/*
 * Copyright (c) 2016 Open-RnD Sp. z o.o.
 * Copyright (c) 2020 Nordic Semiconductor ASA
 *
 * SPDX-License-Identifier: Apache-2.0
 */

#include <zephyr.h>
#include <device.h>
#include <drivers/gpio.h>
#include <sys/util.h>
#include <sys/printk.h>
#include <inttypes.h>
#include <string.h>

#define SLEEP_TIME_MS 3
/*
 * Get button configuration from the devicetree sw0 alias. This is mandatory.
 * !!!!!! reconfig the official dts files using .overlay file
 * here we define 7 buttons for simulation
 */
#define SW0_NODE	DT_ALIAS(sw0)
#define SW1_NODE	DT_ALIAS(sw1)
#define SW2_NODE	DT_ALIAS(sw2)
#define SW3_NODE	DT_ALIAS(sw3)
#define SW4_NODE	DT_ALIAS(sw4)
#define SW5_NODE	DT_ALIAS(sw5)
#define SW6_NODE	DT_ALIAS(sw6)
#if !DT_NODE_HAS_STATUS(SW0_NODE, okay) || !DT_NODE_HAS_STATUS(SW1_NODE, okay) // skip other node if not necessary
#error "Unsupported board: devicetree alias is not defined"
#endif

/* 
gpios = <&gpio0 11 (GPIO_PULL_UP | GPIO_ACTIVE_LOW)>; 
struct gpio_dt_spec {
	const struct device *port;
	gpio_pin_t pin;
	gpio_dt_flags_t dt_flags;
};
*/
extern unsigned char messages[5];

static const struct gpio_dt_spec buttons[7] = {
    GPIO_DT_SPEC_GET_OR(SW0_NODE, gpios, {0}),
    GPIO_DT_SPEC_GET_OR(SW1_NODE, gpios, {0}),
    GPIO_DT_SPEC_GET_OR(SW2_NODE, gpios, {0}),
    GPIO_DT_SPEC_GET_OR(SW3_NODE, gpios, {0}),
    GPIO_DT_SPEC_GET_OR(SW4_NODE, gpios, {0}),
    GPIO_DT_SPEC_GET_OR(SW5_NODE, gpios, {0}),
    GPIO_DT_SPEC_GET_OR(SW6_NODE, gpios, {0}),
};

/*
struct gpio_callback {
	sys_snode_t node;
	gpio_callback_handler_t handler;
	gpio_port_pins_t pin_mask;
};
*/
static struct gpio_callback button_cb_data[7];

// define callback handler named button_pressed
void button_pressed(const struct device *dev, struct gpio_callback *cb,
		    uint32_t pins);
void button_check(void);
void button_loop(void);
```

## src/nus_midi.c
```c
/*
 * Copyright (c) 2018 Nordic Semiconductor ASA
 *
 * SPDX-License-Identifier: LicenseRef-Nordic-5-Clause
 */

#include <bluetooth/conn.h>
#include <bluetooth/uuid.h>
#include <bluetooth/gatt.h>

#include "nus_midi.h"
#include <logging/log.h>
#define CONFIG_BT_NUS_LOG_LEVEL 3
LOG_MODULE_REGISTER(bt_nus, CONFIG_BT_NUS_LOG_LEVEL);

static struct bt_nus_cb nus_cb;

static void nus_ccc_cfg_changed(const struct bt_gatt_attr *attr,
				  uint16_t value)
{
	if (nus_cb.send_enabled) {
		LOG_DBG("Notification has been turned %s",
			value == BT_GATT_CCC_NOTIFY ? "on" : "off");
		nus_cb.send_enabled(value == BT_GATT_CCC_NOTIFY ?
			BT_NUS_SEND_STATUS_ENABLED : BT_NUS_SEND_STATUS_DISABLED);
	}
}

// static ssize_t on_receive(struct bt_conn *conn,
// 			  const struct bt_gatt_attr *attr,
// 			  const void *buf,
// 			  uint16_t len,
// 			  uint16_t offset,
// 			  uint8_t flags)
// {
// 	LOG_DBG("Received data, handle %d, conn %p",
// 		attr->handle, (void *)conn);

// 	if (nus_cb.received) {
// 		nus_cb.received(conn, buf, len);
// }
// 	return len;
// }

static void on_sent(struct bt_conn *conn, void *user_data)
{
	ARG_UNUSED(user_data);

	LOG_DBG("Data send, conn %p", (void *)conn);

	if (nus_cb.sent) {
		nus_cb.sent(conn);
	}
}

/* UART Service Declaration */
BT_GATT_SERVICE_DEFINE(nus_svc,
BT_GATT_PRIMARY_SERVICE(MIDI_BT_UUID_NUS_SERVICE),
	BT_GATT_CHARACTERISTIC(MIDI_BT_UUID_NUS_TX,
				   BT_GATT_CHRC_READ |
				   BT_GATT_CHRC_WRITE_WITHOUT_RESP |
				   BT_GATT_CHRC_NOTIFY,
			       BT_GATT_PERM_READ | BT_GATT_PERM_WRITE,
			       NULL, NULL, NULL),
	BT_GATT_CCC(nus_ccc_cfg_changed, BT_GATT_PERM_READ | BT_GATT_PERM_WRITE),
	// BT_GATT_CHARACTERISTIC(MIDI_BT_UUID_NUS_RX,
	// 		       BT_GATT_CHRC_WRITE |
	// 		       BT_GATT_CHRC_WRITE_WITHOUT_RESP,
	// 		       BT_GATT_PERM_READ | BT_GATT_PERM_WRITE,
	// 		       NULL, on_receive, NULL),
);

int bt_nus_init(struct bt_nus_cb *callbacks)
{
	if (callbacks) {
		nus_cb.received = callbacks->received;
		nus_cb.sent = callbacks->sent;
		nus_cb.send_enabled = callbacks->send_enabled;
	}

	return 0;
}

int bt_nus_send(struct bt_conn *conn, const char *data, uint16_t len)
{
	struct bt_gatt_notify_params params = {0};
	const struct bt_gatt_attr *attr = &nus_svc.attrs[2];

	params.attr = attr;
	params.data = data;
	params.len = len;
	params.func = on_sent;

	if (!conn) {
		LOG_DBG("Notification send to all connected peers");
		return bt_gatt_notify_cb(NULL, &params);
	} else if (bt_gatt_is_subscribed(conn, attr, BT_GATT_CCC_NOTIFY)) {
		return bt_gatt_notify_cb(conn, &params);
	} else {
		return -EINVAL;
	}
}
```

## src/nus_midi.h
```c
/*
 * Copyright (c) 2018 Nordic Semiconductor ASA
 *
 * SPDX-License-Identifier: LicenseRef-Nordic-5-Clause
 */

#ifndef BT_NUS_H_
#define BT_NUS_H_

/**
 * @file
 * @defgroup bt_nus Nordic UART (NUS) GATT Service
 * @{
 * @brief Nordic UART (NUS) GATT Service API.
 */

#include <zephyr/types.h>
#include <bluetooth/conn.h>
#include <bluetooth/uuid.h>
#include <bluetooth/gatt.h>

#ifdef __cplusplus
extern "C" {
#endif
/** @brief UUID of the MIDI Service. **/
#define MIDI_BT_UUID_NUS_VAL \
	BT_UUID_128_ENCODE(0x03b80e5a, 0xede8, 0x4b33, 0xa751, 0x6ce34ec4c700)

/** @brief UUID of the MIDI TX Characteristic. **/
#define MIDI_BT_UUID_NUS_TX_VAL \
	BT_UUID_128_ENCODE(0x7772e5db, 0x3868, 0x4112, 0xa1a9, 0xf2669d106bf3)

/** @brief UUID of the NUS RX Characteristic. **/
#define MIDI_BT_UUID_NUS_RX_VAL \
	BT_UUID_128_ENCODE(0x6e400002, 0xb5a3, 0xf393, 0xe0a9, 0xe50e24dcca9e)

#define MIDI_BT_UUID_NUS_SERVICE   BT_UUID_DECLARE_128(MIDI_BT_UUID_NUS_VAL)
#define MIDI_BT_UUID_NUS_TX        BT_UUID_DECLARE_128(MIDI_BT_UUID_NUS_TX_VAL)
#define MIDI_BT_UUID_NUS_RX        BT_UUID_DECLARE_128(MIDI_BT_UUID_NUS_RX_VAL)

/* Channel messages.
   4 most significant bytes is the type, 4 least significant is the channel.
   Example: 0x83 is note off channel 4*/
#define MIDI_CH_NOTE_OFF                  0x80
#define MIDI_CH_NOTE_ON                   0x90
#define MIDI_CH_POLY_AFTER_TOUCH          0xA0
#define MIDI_CH_CTRL_CHANGE               0xB0
#define MIDI_CH_PRGM_CAHNGE               0xC0
#define MIDI_CH_CHANNEL_AFTER_TOUCH       0xD0
#define MIDI_CH_PITCH_WHEEL               0xE0

/* System Exclusive. */
#define MIDI_SYS_SYSEX_START      0xF0
#define MIDI_SYS_SYSEX_END        0xF7

/* System Common. */
#define MIDI_SYS_CMN_FRAME        0xF1
#define MIDI_SYS_CMN_SONG_POINTER 0xF2
#define MIDI_SYS_CMN_SONG_SELECT  0xF3
#define MIDI_SYS_CMN_TUNE_REQUEST 0xF6

/* System Real-Time. */
#define MIDI_SYS_RT_TIMING        0xF8
#define MIDI_SYS_RT_START         0xFA
#define MIDI_SYS_RT_CONTINUE      0xFB
#define MIDI_SYS_RT_STOP          0xFC
#define MIDI_SYS_RT_SENSE         0xFE
#define MIDI_SYS_RT_RESET         0xFF

/* Midi channels
   4 most significant bytes is the type, 4 least significant is the channel.
   Example: 0x83 is note off channel 4 */

#define MIDI_CHANNEL_1  0x00
#define MIDI_CHANNEL_2  0x01
#define MIDI_CHANNEL_3  0x02
#define MIDI_CHANNEL_4  0x03
#define MIDI_CHANNEL_5  0x04
#define MIDI_CHANNEL_6  0x05
#define MIDI_CHANNEL_7  0x06
#define MIDI_CHANNEL_8  0x07
#define MIDI_CHANNEL_9  0x08
#define MIDI_CHANNEL_10 0x09
#define MIDI_CHANNEL_11 0x0A
#define MIDI_CHANNEL_12 0x0B
#define MIDI_CHANNEL_13 0x0C
#define MIDI_CHANNEL_14 0x0D
#define MIDI_CHANNEL_15 0x0E
#define MIDI_CHANNEL_16 0x0F

#define MIDI_CHANNEL_MIN  MIDI_CHANNEL_1
#define MIDI_CHANNEL_MAX  MIDI_CHANNEL_16

#define MIDI_VELOCITY_MAX 0x7F
#define MIDI_NOTE_MAX     0x7F
#define MIDI_DATA_MAX     0x7F

/*Example note values as defines. Common to have Middle C as 0x3C. 128 Notes in total. */
#define MIDI_NOTE_C8          0x78
#define MIDI_NOTE_C7          0x6C
#define MIDI_NOTE_C6          0x60
#define MIDI_NOTE_C5          0x54
#define MIDI_NOTE_C4          0x48
#define MIDI_NOTE_C3          0x3C
#define MIDI_NOTE_C2          0x30
#define MIDI_NOTE_C1          0x24
#define MIDI_NOTE_C0          0x18
#define MIDI_NOTE_C_MINUS_1   0x0C
#define MIDI_NITE_C_MINUS_2   0x00

/*Example MIDI Data Package */
#define MIDI_Package_C_Note 0x80 0x80 0x90 0x3C 0x7F
//Header-0x80 Timestamp-0x80 Status-0x90 MIDI_NOTE_C3-0x3C MIDI_VELOCITY_MAX-0x7F
#define MIDI_Package_C_Chord 0x80 0x80 0x90 0x3C 0x7F 0x80 0x90 0x40 0x7F 0x44 0x7F //C, E and G Notes
//Header-0x80 Timestamp-0x80 Status-0x90 MIDI_NOTE_C3-0x3C MIDI_VELOCITY_MAX-0x7F
//Timestamp-0x80 Status-0x90 MIDI_NOTE_E3-0x40 MIDI_VELOCITY_MAX-0x7F MIDI_NOTE_G3-0x44 MIDI_VELOCITY_MAX-0x7F

/** @brief NUS send status. */
enum bt_nus_send_status {
	/** Send notification enabled. */
	BT_NUS_SEND_STATUS_ENABLED,
	/** Send notification disabled. */
	BT_NUS_SEND_STATUS_DISABLED,
};

/** @brief Pointers to the callback functions for service events. */
struct bt_nus_cb {
	/** @brief Data received callback.
	 *
	 * The data has been received as a write request on the NUS RX
	 * Characteristic.
	 *
	 * @param[in] conn  Pointer to connection object that has received data.
	 * @param[in] data  Received data.
	 * @param[in] len   Length of received data.
	 */
	void (*received)(struct bt_conn *conn,
			 const uint8_t *const data, uint16_t len);

	/** @brief Data sent callback.
	 *
	 * The data has been sent as a notification and written on the NUS TX
	 * Characteristic.
	 *
	 * @param[in] conn Pointer to connection object, or NULL if sent to all
	 *                 connected peers.
	 */
	void (*sent)(struct bt_conn *conn);

	/** @brief Send state callback.
	 *
	 * Indicate the CCCD descriptor status of the NUS TX characteristic.
	 *
	 * @param[in] status Send notification status.
	 */
	void (*send_enabled)(enum bt_nus_send_status status);

};

/**@brief Initialize the service.
 *
 * @details This function registers a GATT service with two characteristics,
 *          TX and RX. A remote device that is connected to this service
 *          can send data to the RX Characteristic. When the remote enables
 *          notifications, it is notified when data is sent to the TX
 *          Characteristic.
 *
 * @param[in] callbacks  Struct with function pointers to callbacks for service
 *                       events. If no callbacks are needed, this parameter can
 *                       be NULL.
 *
 * @retval 0 If initialization is successful.
 *           Otherwise, a negative value is returned.
 */
int bt_nus_init(struct bt_nus_cb *callbacks);

/**@brief Send data.
 *
 * @details This function sends data to a connected peer, or all connected
 *          peers.
 *
 * @param[in] conn Pointer to connection object, or NULL to send to all
 *                 connected peers.
 * @param[in] data Pointer to a data buffer.
 * @param[in] len  Length of the data in the buffer.
 *
 * @retval 0 If the data is sent.
 *           Otherwise, a negative value is returned.
 */
int bt_nus_send(struct bt_conn *conn, const char *data, uint16_t len);

/**@brief Get maximum data length that can be used for @ref bt_nus_send.
 *
 * @param[in] conn Pointer to connection Object.
 *
 * @return Maximum data length.
 */
static inline uint32_t bt_nus_get_mtu(struct bt_conn *conn)
{
	/* According to 3.4.7.1 Handle Value Notification off the ATT protocol.
	 * Maximum supported notification is ATT_MTU - 3 */
	return bt_gatt_get_mtu(conn) - 3;
}

#ifdef __cplusplus
}
#endif

/**
 *@}
 */

#endif /* BT_NUS_H_ */
```
